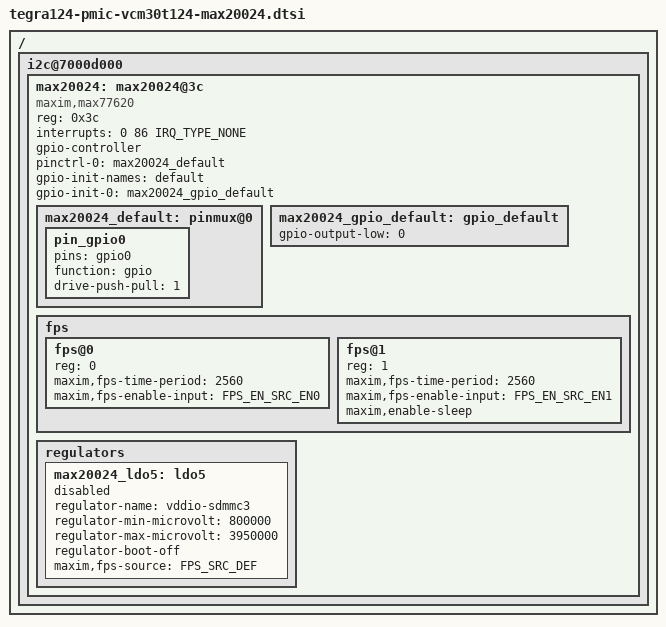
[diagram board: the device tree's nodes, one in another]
#include <dt-bindings/mfd/max77620.h>

/ {
	i2c@7000d000 {
		max20024: max20024@3c {
			/* Max20024 and Max77620 are identical in register map
			 * and interpretation of all fields. So compatible with
			 * max77620
			 */
			compatible = "maxim,max77620";
			reg = <0x3c>;
			interrupts = <0 86 IRQ_TYPE_NONE>;

			gpio-controller;
			#gpio-cells = <2>;

			/* These entries for configuring the GPIO0 of max20024
			 * as EN_VDD_FUSE
			 */
			pinctrl-names = "default";
			pinctrl-0 = <&max20024_default>;

			gpio-init-names = "default";
			gpio-init-0 = <&max20024_gpio_default>;

			max20024_default: pinmux@0 {
				pin_gpio0 {
					pins = "gpio0";
					function = "gpio";
					drive-push-pull = <1>;
				};
			};

			max20024_gpio_default:gpio_default {
				gpio-output-low = <0>;
			};

			fps {
				#address-cells = <1>;
				#size-cells = <0>;
				fps@0 {
					reg = <0>;
					maxim,fps-time-period = <2560>;
					maxim,fps-enable-input = <FPS_EN_SRC_EN0>;
				};

				fps@1 {
					reg = <1>;
					maxim,fps-time-period = <2560>;
					maxim,fps-enable-input = <FPS_EN_SRC_EN1>;
					maxim,enable-sleep;
				};

			};

			regulators {
				max20024_ldo5: ldo5 {
					regulator-name = "vddio-sdmmc3";
					regulator-min-microvolt = <800000>;
					regulator-max-microvolt = <3950000>;
					regulator-boot-off;
					maxim,fps-source = <FPS_SRC_DEF>;
					status = "disabled";
				};
			};
		};
	};
};
